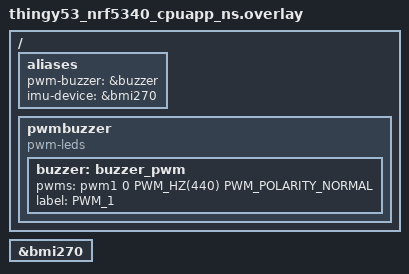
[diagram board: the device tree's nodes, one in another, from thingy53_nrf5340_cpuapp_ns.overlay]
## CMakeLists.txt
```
# SPDX-License-Identifier: Apache-2.0

cmake_minimum_required(VERSION 3.20.0)

find_package(Zephyr REQUIRED HINTS $ENV{ZEPHYR_BASE})
project(Gesture_Game)

target_sources(app PRIVATE src/main.c)
target_sources(app PRIVATE src/led.c)
target_sources(app PRIVATE src/button.c)
target_sources(app PRIVATE src/state_machine.c)
target_sources(app PRIVATE src/buzzer.c)
target_sources(app PRIVATE src/imu.c)
```

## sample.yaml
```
sample: 
  description: Gesture game for MES project
  name: Thingy53-NRF5340-network-MCU
type: mcu
arch: arm
supported:
  - watchdog
  - pwm
  - gpio
```

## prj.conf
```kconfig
# enable PWM
CONFIG_PWM=y

CONFIG_GPIO=y

CONFIG_SENSOR=y

#CONFIG_I2C=y
CONFIG_SPI=y
CONFIG_MULTITHREADING=y
CONFIG_NEWLIB_LIBC=y

CONFIG_NCS_SAMPLE_MCUMGR_BT_OTA_DFU=y
CONFIG_NCS_SAMPLE_MCUMGR_BT_OTA_DFU_SPEEDUP=y

#CONFIG_BT=y
#CONFIG_BT_PERIPHERAL=y
CONFIG_BT_DEVICE_NAME="Thingy53"
```

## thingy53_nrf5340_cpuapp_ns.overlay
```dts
// To get started, press Ctrl+Space to bring up the completion menu and view the available nodes.

// You can also use the buttons in the sidebar to perform actions on nodes.
// Actions currently available include:

// * Enabling / disabling the node
// * Adding the bus to a bus
// * Removing the node
// * Connecting ADC channels

// For more help, browse the DeviceTree documentation at https://docs.zephyrproject.org/latest/guides/dts/index.html
// You can also visit the nRF DeviceTree extension documentation at https://nrfconnect.github.io/vscode-nrf-connect/devicetree/nrfdevicetree.html

/ {
	aliases {
		pwm-buzzer = &buzzer;
		imu-device = &bmi270;
	};
	pwmbuzzer {
		compatible = "pwm-leds";
		status = "okay";
		buzzer:buzzer_pwm {
			pwms = <&pwm1 0 PWM_HZ(440) PWM_POLARITY_NORMAL>;
			label = "PWM_1";
		};
	};
};
&bmi270 {
	status = "okay";
};
```

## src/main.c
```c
/*
 * Copyright (c) 2012-2014 Wind River Systems, Inc.
 *
 * SPDX-License-Identifier: Apache-2.0
 */

#include <zephyr/kernel.h>
#include <zephyr/device.h>
#include <zephyr/drivers/pwm.h>
#include <zephyr/drivers/gpio.h>
#include <zephyr/drivers/sensor.h>
#include "buzzer.h"
#include "state_machine.h"
#include "imu.h"
#include "led.h"


int main(void)
{

	return 0;
}

// led is up: -9 And led is down: +9 looking for 9 -- gravity 9 m/s^2
// when there is no movement G should be close to 0. when there is movement and accel is settling 
// G should not be 0. The sum of squares of A is consistent if i'm not moving. This is the magnatitude
//
```

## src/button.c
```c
/*
 * Copyright (c) 2024
 *
 * SPDX-License-Identifier: Apache-2.0
 */


#include <zephyr/kernel.h>
#include <zephyr/drivers/gpio.h>
#include <zephyr/device.h>
#include "button.h"
#include "state_machine.h"

#define QUICK_PRESS_DEBOUNCE_TIME_MS   10

uint8_t num_presses = 0;
volatile uint8_t accept_button_presses = 0;

static const struct gpio_dt_spec sUser_btn = GPIO_DT_SPEC_GET(DT_ALIAS(sw0),gpios);
static struct gpio_callback button_cb_data;
static struct k_work timer_work;
static struct k_timer debounce_timer;

void button_debounce_workq_submit() // when timer expires submit for work to be done
{
    if (k_timer_remaining_get(&debounce_timer) == 0){
        k_work_submit(&timer_work);
    }
}
void button_workq()
{
    if (num_presses < 3){
        num_presses++;
    }
    else num_presses = 0;
}
static void button_press_isr(const struct device *dev, struct gpio_callback *cb, uint32_t pins)
{
    k_timer_start(&debounce_timer, K_MSEC(QUICK_PRESS_DEBOUNCE_TIME_MS), K_MSEC(0));
}

static void configure_button_interrupt()
{
    gpio_init_callback(&button_cb_data,button_press_isr,BIT(sUser_btn.pin));
	gpio_add_callback(sUser_btn.port, &button_cb_data);
}

static void configure_button_timer()
{
     /* Initialize button debounce timer work queue */
    k_work_init(&timer_work,button_workq);

    /* Initialize button debounce timer */
    k_timer_init(&debounce_timer,button_debounce_workq_submit, NULL);
}

static void button_gpio_init()
{
    int err; 
    if (!device_is_ready(sUser_btn.port)){
        printk("Error %d: failed to configure %s pin %d\n",
        err, sUser_btn.port->name,sUser_btn.pin);
    }

    err = gpio_pin_configure_dt(&sUser_btn,GPIO_INPUT);
	if (err != 0){
		printk("Error %d: failed to configure %s pin %d\n",
		err, sUser_btn.port->name, sUser_btn.pin);
	}

    err = gpio_pin_interrupt_configure_dt(&sUser_btn, GPIO_INT_EDGE_TO_ACTIVE);
	if (err !=0){
		printk("Error %d: failed to configure interrupt %s pin %d\n",
		err, sUser_btn.port->name, sUser_btn.pin);
	}
}

static int button_init()
{
    button_gpio_init();
    configure_button_timer();
    configure_button_interrupt();
    return 0;
}

SYS_INIT(button_init, APPLICATION, CONFIG_APPLICATION_INIT_PRIORITY);
```

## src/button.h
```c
/*
 * Copyright (c) 2024
 *
 * SPDX-License-Identifier: Apache-2.0
 */

#ifndef _BUTTON_H_
#define _BUTTON_H_

#include <zephyr/kernel.h>

void button_debounce_workq_submit();
void button_workq();

extern uint8_t num_presses;


#endif
```

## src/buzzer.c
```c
/*
 * Copyright (c) 2012-2014 Wind River Systems, Inc.
 *
 * SPDX-License-Identifier: Apache-2.0
 */

#include <zephyr/kernel.h>
#include <zephyr/init.h>
#include <zephyr/device.h>
#include <zephyr/drivers/pwm.h>
#include <zephyr/drivers/sensor.h>
#include <stdlib.h>
#include <time.h>
#include "buzzer.h"
#include "imu.h"
#include "utils.h"
#include "led.h"
#include "state_machine.h"

#define BUZZER_STACK                1024
#define STARTUP_NOTES               15
#define GOODBYE_NOTES               15
#define CONGRATES_NOTES             13
#define SEVEN_NOTES                 7
#define SIX_NOTES                   6
#define LOWER_BOUND                 0
#define UPPER_BOUND                 5
#define LEVEL_ONE_NOTES             10
#define LEVEL_TWO_NOTES             16
#define LEVEL_THREE_NOTES           22
#define HIGH_SCORE_LEVEL_ONE        5
#define HIGH_SCORE_LEVEL_TWO        8  
#define HIGH_SCORE_LEVEL_THREE      11

static const struct pwm_dt_spec sBuzzer = PWM_DT_SPEC_GET(DT_ALIAS(pwm_buzzer));
const char *ORIENTATION_STRING[SEVEN_NOTES] = {
    "UP", "DOWN", "RIGHT", "LEFT","RIGHTSIDE_UP", "UPSIDE_DOWN", "INVALID",
};

enum song_choice
{
    silence,
    startup_sound,
    congrats_sound,
    goodbye_sound,
    test
};
struct notes_highscore
{
    int notes_per_level;
    int highest_score;
};

struct note_duration
{   
    int note; // hz
    int duration; //
};

struct note_side
{   
    int note;
    int side;
    int duration; 
};

struct notes_highscore level1_scoreboard = {
    .notes_per_level= LEVEL_ONE_NOTES, .highest_score = HIGH_SCORE_LEVEL_ONE
};
struct notes_highscore level2_scoreboard = {
    .notes_per_level= LEVEL_TWO_NOTES,.highest_score = HIGH_SCORE_LEVEL_TWO
};
struct notes_highscore level3_scoreboard = {
    .notes_per_level= LEVEL_THREE_NOTES,.highest_score = HIGH_SCORE_LEVEL_THREE
};

struct note_side user_action[SIX_NOTES] = {
    {.note = A4, .side = up, .duration = whole },
    {.note = B4, .side = down, .duration = whole},
    {.note = C5, .side = right, .duration = whole},
    {.note = D5, .side = left, .duration = whole},
    {.note = E5, .side = rightside_up, .duration = whole},
    {.note = F5, .side = upside_down, .duration = whole}
};

struct note_duration startup_song[STARTUP_NOTES] = {
    {.note= F4, .duration = quarter},
    {.note= F4, .duration = quarter},
    {.note= G4, .duration = quarter},
    {.note= A4, .duration = quarter},
    {.note= Bb4, .duration = quarter},
    {.note= G4, .duration = quarter},
    {.note= F4, .duration = quarter},
    {.note= Bb4, .duration = quarter},
    {.note= Bb4, .duration = quarter},
    {.note= C5, .duration = quarter},
    {.note= D5, .duration = quarter},
    {.note= Bb4, .duration = quarter},
    {.note= C5, .duration = quarter},
    {.note= A4, .duration = quarter},
    {.note= Bb4, .duration = half_note}
};

struct note_duration goodbye_song[GOODBYE_NOTES] = {
    {.note= F4, .duration = eigth},
    {.note= F4, .duration = eigth},
    {.note= G4, .duration = eigth},
    {.note= A4, .duration = eigth},
    {.note= Bb4, .duration = eigth},
    {.note= G4, .duration = eigth},
    {.note= F4, .duration = eigth},
    {.note= Bb4, .duration = eigth},
    {.note= Bb4, .duration = eigth},
    {.note= C5, .duration = eigth},
    {.note= D5, .duration = eigth},
    {.note= Bb4, .duration = eigth},
    {.note= C5, .duration = eigth},
    {.note= A4, .duration = eigth},
    {.note= Bb4, .duration = quarter}
};

struct note_duration congrats_song[CONGRATES_NOTES] = {
    {.note= G4, .duration = quarter},
    {.note= G4, .duration = quarter},
    {.note= A4, .duration = eigth},
    {.note= Bb4, .duration = half_note},
    {.note= F4, .duration = quarter},
    {.note= F4, .duration = quarter},
    {.note= F4, .duration = quarter},
    {.note= C5, .duration = quarter},
    {.note= C5, .duration = quarter},
    {.note= C5, .duration = quarter},
    {.note= Bb4, .duration = eigth},
    {.note= A4, .duration = quarter},
    {.note= G4, .duration = whole}
};

enum song_choice eSong = silence; 
uint8_t tone_done = 0; 
volatile uint8_t user_won =0;

K_SEM_DEFINE(buzzer_initialize_sem, 0,1); // wait until buzzer is initiailzed 
K_SEM_DEFINE(play_game_sem, 0,1); // wait until the thread is called
K_MUTEX_DEFINE(tone_done_mutex); // wait until buzzer is initiailzed 

void buzzer_thread_func(void *d0,void *d1,void *d2)
{
    /* Block until buzzer is available */
    k_sem_take(&buzzer_initialize_sem,K_FOREVER); 
    while(1) 
    {
        switch (eSong)
        {
            case silence: 
                pwm_set_pulse_dt(&sBuzzer, 0);
                k_sleep(K_FOREVER);
                break;
            case startup_sound:
                printk("starting sound\r\n");
                k_mutex_lock(&tone_done_mutex, K_FOREVER);
                for (int i = 0; i < STARTUP_NOTES;i++)
                {
                    pwm_set_dt(&sBuzzer,PWM_HZ(startup_song[i].note),PWM_HZ(startup_song[i].note)/2U); 
                    k_msleep(startup_song[i].duration); // not sleeping the processor it's sleeping the thread. it's started the PWM. 
                }
                pwm_set_pulse_dt(&sBuzzer, 0);
                printk("in buzzer.done with start up tone\r\n");
                k_mutex_unlock(&tone_done_mutex);
                wake_state_machine_thd();
                k_sleep(K_FOREVER); // sleep the buzzer thread
                break;
            case goodbye_sound: 
                k_mutex_lock(&tone_done_mutex, K_FOREVER);
                for (int i = 0; i < GOODBYE_NOTES;i++)
                {
                    pwm_set_dt(&sBuzzer,PWM_HZ(goodbye_song[i].note),PWM_HZ(goodbye_song[i].note)/2U); 
                    k_msleep(goodbye_song[i].duration);
                }
                pwm_set_pulse_dt(&sBuzzer, 0);
                printk("in buzzer.done with goodbye tone\r\n");
                k_mutex_unlock(&tone_done_mutex);
                wake_state_machine_thd();
                k_sleep(K_FOREVER);
                break;
            case test: 
                k_mutex_lock(&tone_done_mutex, K_FOREVER);
                /*printk("side: %s\n", ORIENTATION_STRING[device_side]);
                for (int i = 0; i < SIX_NOTES;i++)
                {
                    if (device_side == user_action[i].side)
                    {
                        pwm_set_dt(&sBuzzer,PWM_HZ(user_action[i].note),PWM_HZ(user_action[i].note)/2U); 
                        k_msleep(user_action[i].duration);
                    }
                    else pwm_set_pulse_dt(&sBuzzer, 0);
                }
                pwm_set_pulse_dt(&sBuzzer, 0);*/
                k_mutex_unlock(&tone_done_mutex);
                break;
            case congrats_sound:
                k_mutex_lock(&tone_done_mutex, K_FOREVER);
                for (int i = 0; i < CONGRATES_NOTES;i++)
                {
                    pwm_set_dt(&sBuzzer,PWM_HZ(congrats_song[i].note),PWM_HZ(congrats_song[i].note)/2U); 
                    k_msleep(congrats_song[i].duration); // not sleeping the processor it's sleeping the thread. it's started the PWM. 
                }
                pwm_set_pulse_dt(&sBuzzer, 0);
                printk("in buzzer.done with congrats_sound\r\n");
                k_mutex_unlock(&tone_done_mutex);
                wake_state_machine_thd();
                k_sleep(K_FOREVER);
                break;
        }
        
    }
}
void play_level(struct notes_highscore sNotes_Higherscore)
{   
    uint8_t user_score = 0;
    int i = 0;
    int device_side;
    srand(time(NULL)); // initialization of random num generator 
    int rand_num;
    while(i < sNotes_Higherscore.notes_per_level)
    {
        rand_num = (rand() % (UPPER_BOUND - LOWER_BOUND + 1)) + LOWER_BOUND;
        pwm_set_dt(&sBuzzer,PWM_HZ(user_action[rand_num].note),PWM_HZ(user_action[rand_num].note)/2U);
        k_msleep(user_action[rand_num].duration);
        pwm_set_pulse_dt(&sBuzzer, 0);
        
        printk("PLAYED TONE. rotate to side:%s \r\n", ORIENTATION_STRING[user_action[rand_num].side]);
        device_side = imu_data_processing();
        
        printk("rotated to side:%s \r\n", ORIENTATION_STRING[device_side]);
        if (device_side == user_action[rand_num].side)
        {
            printk("Matched!\r\n");
            user_score++;
        }
        else {
            printk("Did not match!\r\n");
            led_error();
            pwm_set_dt(&sBuzzer,PWM_HZ(C4),PWM_HZ(C4)/2U);
            k_msleep(whole);
            pwm_set_pulse_dt(&sBuzzer, 0);
        }
        if (user_score >= sNotes_Higherscore.highest_score)
        {
            printk("User won!\r\n");
            user_won = 1;
        }
        else 
        {
            printk("still playing!\r\n");
            i++;
        }
    }
    printk("played the game..waking up state machine\r\n");
}


K_THREAD_DEFINE(buzzer_thd,BUZZER_STACK,buzzer_thread_func,NULL,NULL,NULL,THREAD1_PRIORITY,0,5000);

void play_startup_song()
{
    eSong = startup_sound;
    printk("woke up buzzer thread\r\n");
    k_wakeup(buzzer_thd);
    k_sleep(K_FOREVER); // sleep SM
}
void play_goodbye_song()
{
    eSong = goodbye_sound;
    k_wakeup(buzzer_thd);
    k_sleep(K_FOREVER);
}
void play_congrats_song()
{
    eSong = congrats_sound;
    k_wakeup(buzzer_thd);
    k_sleep(K_FOREVER); // sleep the SM
}
void play_test()
{
    eSong = test;
    k_wakeup(buzzer_thd);
    //k_sleep(K_FOREVER);
}
void play_silence()
{
    eSong = silence;
    k_wakeup(buzzer_thd);
   // k_sleep(K_FOREVER);
}

void wake_buzzer_thd()
{
    k_wakeup(buzzer_thd);
}

void play_level_one()
{
    k_sem_give(&play_game_sem);
    play_level(level1_scoreboard); // SM is not asleep here
}
void play_level_two()
{
    k_sem_give(&play_game_sem);
    play_level(level2_scoreboard); // SM is not asleep here
}
void play_level_three()
{
    k_sem_give(&play_game_sem);
    play_level(level3_scoreboard); // SM is not asleep here
}
static int buzzer_init()
{
    int ret = 0;
    if (!device_is_ready(sBuzzer.dev))
	{                          
		printk("Device %s is not ready.\r\n",sBuzzer.dev->name);
        ret = 1;
	}

    k_sem_give(&buzzer_initialize_sem);
    return 0;
}

SYS_INIT(buzzer_init, APPLICATION, CONFIG_APPLICATION_INIT_PRIORITY);
```

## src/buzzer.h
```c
#ifndef _BUZZER_H_
#define _BUZZER_H_

#include "utils.h"

extern void play_startup_song();
extern void play_congrats_song();
extern void play_goodbye_song();
extern void play_goodbye_song();
extern void play_test();
extern void play_silence();
extern void play_level_one();
extern void play_level_two();
extern void play_level_three();
extern void wake_buzzer_thd();
extern void device_side_translation();
extern uint8_t tone_done;
extern volatile uint8_t user_won;

enum orientation 
{
    up,
    down,
    right,
    left,
    rightside_up,
    upside_down, 
    invalid_side,
    invalid_gyr
};
extern enum orientation eSide;

#define whole       600 //whole note
#define eigth       75 //eigth note
#define quarter     150
#define half_note   300

#define C4  262
#define F4  349
#define G4  392
#define A4  440
#define Bb4 466
#define B4  494
#define C5  523
#define D5  587  
#define E5  659
#define F5  698
#define G5  784
#define A5  880

#define REST 1

#endif
```

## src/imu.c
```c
/*
 * Copyright (c) 2024
 *
 * SPDX-License-Identifier: Apache-2.0
 */
#include <zephyr/device.h>
#include <zephyr/init.h>
#include <zephyr/drivers/pwm.h>
#include <zephyr/drivers/gpio.h>
#include <zephyr/drivers/sensor.h>
#include <zephyr/kernel.h>
#include "imu.h"
#include "buzzer.h"
#include "state_machine.h"

#define IMU_STACK    1024
#define GRAVITY         9
#define NEG_GRAVITY    -9

static const struct device *sIMU_device = DEVICE_DT_GET_ONE(bosch_bmi270);
static struct sensor_value acc[3], gyr[3];
static struct sensor_value full_scale,sampling_freq,oversampling;
static int device_side;

K_SEM_DEFINE(imu_initialize_sem,0,1); // wait until buzzer is initiailzed 
K_MUTEX_DEFINE(imu_processing_mutex); // wait until buzzer is initiailzed 

static int imu_init()
{
    int err;
    if (!device_is_ready(sIMU_device))
    {
		printk("Error %d: failed to configure %s\n",
		err, sIMU_device->name);
	}

    full_scale.val1 = 2;            /* G maximum it can read. it's range/scale */ 
    full_scale.val2 = 0;
    sampling_freq.val1 = 15;       /* Hz. Performance mode. Faster = more sampling/note. Don't want to move fast */
    sampling_freq.val2 = 0;
    oversampling.val1 = 1;          /* Normal mode. oversample and filter out the extra data */
    oversampling.val2 = 0;

    /* Setting scale in G, due to loss of precision if the SI unit m/s^2
        * is used
        */
    sensor_attr_set(sIMU_device,SENSOR_CHAN_ACCEL_XYZ,SENSOR_ATTR_FULL_SCALE,&full_scale);
    sensor_attr_set(sIMU_device,SENSOR_CHAN_ACCEL_XYZ,SENSOR_ATTR_OVERSAMPLING,&oversampling);
    sensor_attr_set(sIMU_device,SENSOR_CHAN_ACCEL_XYZ,SENSOR_ATTR_SAMPLING_FREQUENCY,&sampling_freq);

    full_scale.val1 = 300;          /* dps. probably too fast */
    full_scale.val2 = 0;
    sampling_freq.val1 = 50;       /* Hz. Performance mode */
    sampling_freq.val2 = 0;
    oversampling.val1 = 1;          /* Normal mode */
    oversampling.val2 = 0;

    sensor_attr_set(sIMU_device,SENSOR_CHAN_GYRO_XYZ,SENSOR_ATTR_FULL_SCALE,&full_scale);
    sensor_attr_set(sIMU_device,SENSOR_CHAN_GYRO_XYZ,SENSOR_ATTR_OVERSAMPLING,&oversampling);
    sensor_attr_set(sIMU_device,SENSOR_CHAN_GYRO_XYZ,SENSOR_ATTR_SAMPLING_FREQUENCY,&sampling_freq);

    k_sem_give(&imu_initialize_sem);
    return 0;
}

void approx_sensor_position(struct sensor_value *acc_pos, struct sensor_value *gyr_pos)
{
   /* Use gyroscope to make sure it's not moving. You can get a false reading if the 
    user shakes the device)*/
    if ((gyr_pos[0].val1 < 1) & (gyr_pos[1].val1< 1) & (gyr_pos[2].val1< 1))
    {
        if ((acc_pos[2].val1 <= NEG_GRAVITY) & (acc_pos[1].val1 < GRAVITY) & (acc_pos[0].val1 < GRAVITY))
        {
            //printk("-z value! up! \r\n"); // -z = up +z = down 
             device_side = up;
        }
        else if ((acc_pos[2].val1 >= GRAVITY) & (acc_pos[1].val1 < GRAVITY)  & (acc_pos[0].val1 < GRAVITY))
        {
           //printk("+z value! down!\r\n"); // -z = up +z = down 
             device_side = down;
        }
        else if ((acc_pos[1].val1 <= NEG_GRAVITY) & (acc_pos[2].val1 < GRAVITY)  & (acc_pos[0].val1 < GRAVITY))
        {
           //printk("-y value! right! \r\n");  // yvalue
             device_side = right;
        }
        else if ((acc_pos[1].val1 >= GRAVITY) & (acc_pos[2].val1 < GRAVITY)  &  (acc_pos[0].val1 < GRAVITY))
        {
           // printk("+y value! left!\r\n"); 
             device_side = left;
        } 
        else if ((acc_pos[0].val1 <= NEG_GRAVITY) & (acc_pos[2].val1 < GRAVITY)  & (acc_pos[1].val1 < GRAVITY))
        {
           // printk("-x value! upside_down! \r\n"); // x value
             device_side = upside_down;
        }
        else if ((acc_pos[0].val1 >= GRAVITY) & (acc_pos[2].val1 < GRAVITY)  & (acc_pos[1].val1 < GRAVITY))
        {
           // printk("+x value! rightside_up!\r\n"); 
             device_side = rightside_up;
        }
        else
        {
             device_side = invalid_side; // on an invalid side
        }
    }
    else
    {
         device_side = invalid_gyr; // move the device too fast

    }
}

void imu_thread_func(void *d0, void *d1, void *d2)
{
    /* Block until imu is available */
    k_sem_take(&imu_initialize_sem,K_FOREVER); 

    while(1)
    {
        /*protect critical section of code without interrupts*/
        k_mutex_lock(&imu_processing_mutex, K_FOREVER);
        while (device_side == invalid_gyr)
        { // keep getting data
            sensor_sample_fetch(sIMU_device);
            sensor_channel_get(sIMU_device, SENSOR_CHAN_GYRO_XYZ, gyr);
            sensor_channel_get(sIMU_device, SENSOR_CHAN_ACCEL_XYZ, acc);

           /* printk("AX: %d.%06d, AY: %d.%06d, AZ: %d.%06d, \n",
                        "GX: %d.%06d, GY: %d.%06d, GZ: %d.%06d,\n",
                        acc[0].val1, acc[0].val2,
                        acc[1].val1, acc[1].val2,
                        acc[2].val1, acc[2].val2);
                        gyr[0].val1, gyr[0].val2,
                        gyr[1].val1, gyr[1].val2,
                        gyr[2].val1, gyr[2].val2);
            */
            approx_sensor_position(acc,gyr);
        }
        k_mutex_unlock(&imu_processing_mutex);
        wake_state_machine_thd(); // call the thread before going to sleep 
        k_sleep(K_FOREVER); // frees up whatever thread is ready to run
    }
}

K_THREAD_DEFINE(imu_thd,IMU_STACK,imu_thread_func,NULL,NULL,NULL,THREAD2_PRIORITY,0,5000);

int imu_data_processing()
{
    k_wakeup(imu_thd); // after i run the imu thread device side is ready to be read
    k_sleep(K_FOREVER); // SM to sleep. I can't go back to SM until the device side is valid.
    
    return device_side;
}

SYS_INIT(imu_init, APPLICATION, CONFIG_APPLICATION_INIT_PRIORITY);
```

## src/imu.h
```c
#ifndef _IMU_H_
#define _IMU_H_


void imu_thread_func(void *d0, void *d1, void *d2);
extern void imu_data_processing();
extern int device_side;

#endif
```

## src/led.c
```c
/*
 * Copyright (c) 2024
 *
 * SPDX-License-Identifier: Apache-2.0
 */

#include <zephyr/init.h>
#include <zephyr/kernel.h>
#include <zephyr/drivers/gpio.h>
#include <zephyr/device.h>
#include "state_machine.h"
#include "led.h"
#include "utils.h"

#define LED_ON                  1
#define LED_OFF                 0
#define ALIVE_LED_PERIOD        500
#define LED_STACK               500 

static const struct gpio_dt_spec sLED_Grn = GPIO_DT_SPEC_GET(DT_ALIAS(led1),gpios);
static const struct gpio_dt_spec sLED_Red = GPIO_DT_SPEC_GET(DT_ALIAS(led2),gpios);
enum eLED_state LED_state;

K_SEM_DEFINE(led_initialize_sem,0,1); // wait until LED is initiailzed 

int led_init()
{
    int err;
    if (!device_is_ready(sLED_Grn.port)){
		printk("Error %d: failed to configure %s pin %d\n",
		err, sLED_Grn.port->name,sLED_Grn.pin);
	}
	err = gpio_pin_configure_dt(&sLED_Grn, GPIO_OUTPUT_INACTIVE);
	if (err != 0){
		printk("Error %d: failed to configure %s pin %d\n",
		err, sLED_Grn.port->name, sLED_Grn.pin);
	}
    if (!device_is_ready(sLED_Red.port)){
		printk("Error %d: failed to configure %s pin %d\n",
		err, sLED_Red.port->name,sLED_Red.pin);
	}
	err = gpio_pin_configure_dt(&sLED_Red, GPIO_OUTPUT_INACTIVE);
	if (err != 0){
		printk("Error %d: failed to configure %s pin %d\n",
		err, sLED_Red.port->name, sLED_Red.pin);
	}
    k_sem_give(&led_initialize_sem);
    return err;
}

void led_thread_func(void *d0,void *d1,void *d2){
 
    k_sem_take(&led_initialize_sem,K_FOREVER); 
    printk("Semaphore taken in LED \r\n");
    uint32_t cnt = 0;
    while (1)
    {
        switch (LED_state)
        {
            case eLED_off:
                gpio_pin_set_dt(&sLED_Grn,LED_OFF);
                gpio_pin_set_dt(&sLED_Red,LED_OFF);
                wake_state_machine_thd();
                k_sleep(K_FOREVER); // the LED thread will go to sleep
                break;
            case eLED_on:
                gpio_pin_set_dt(&sLED_Grn,LED_ON);
                wake_state_machine_thd();
                k_sleep(K_FOREVER); // the LED thread will go to sleep
                break;
            case eLED_blinky: 
                gpio_pin_set_dt(&sLED_Grn,cnt%2);
                k_msleep(ALIVE_LED_PERIOD/2);
                cnt++; 
                break; 
            case eLED_error:
                gpio_pin_set_dt(&sLED_Red,LED_ON);
                wake_state_machine_thd();
                k_sleep(K_FOREVER); // the LED thread will go to sleep
                break;
        }
    }
}

K_THREAD_DEFINE(g_alive_thd,LED_STACK,led_thread_func,NULL,NULL,NULL,THREAD3_PRIORITY,0,5000);

void led_off()
{
    LED_state = eLED_off;
    k_wakeup(g_alive_thd);
    k_sleep(K_FOREVER); // turn of SM thread
    // turn off the current thread so that the LED thread can run or make it go to sleep for some time
}
void led_start()
{   
    LED_state = eLED_on;
    k_wakeup(g_alive_thd);
    k_sleep(K_FOREVER);
    // turn off the current thread so that the LED thread can run or make it go to sleep for some time
}
void led_blinky()
{
    LED_state = eLED_blinky;
    k_wakeup(g_alive_thd); // not sleep SM because want to blink while waiting for user input
    k_sleep(K_FOREVER); // turn of SM thread
}
void led_error()
{
    LED_state = eLED_error;
    k_wakeup(g_alive_thd); 
    k_sleep(K_FOREVER); // turn off the current thread 
}
SYS_INIT(led_init, APPLICATION, CONFIG_APPLICATION_INIT_PRIORITY);
```

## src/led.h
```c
/*
 * Copyright (c) 2024
 *
 * SPDX-License-Identifier: Apache-2.0
 */

#ifndef _LED_H_
#define _LED_H_

enum eLED_state
{
    eLED_off,
    eLED_on,
    eLED_blinky,
    eLED_error
};
extern enum eLED_state LED_state;
extern void led_off();
extern void led_start();
extern void led_blinky();
extern void led_error();

#endif
```

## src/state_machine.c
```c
/*
 * Copyright (c) 2024
 *
 * SPDX-License-Identifier: Apache-2.0
 */


#include <zephyr/init.h>
#include <zephyr/kernel.h>
#include "state_machine.h"
#include "led.h"
#include "button.h"
#include "imu.h"
#include "buzzer.h"
#include "utils.h"

#define STATE_MACHINE_STACK     1024 
static struct k_work select_level_work;
static struct k_timer select_level_timer;
enum state currentState = START;

K_SEM_DEFINE(state_machine_sem, 0,1); // wait until buzzer is initiailzed 

int state_machine_init()
{
    /* work job for selecting level */
    k_work_init(&select_level_work,select_level_workq);
    /* Initialize timer for selecting a level */
    k_timer_init(&select_level_timer,select_level_workq_submit, NULL);
    k_sem_give(&state_machine_sem);
    return 0;
}

void state_machine_func(void *d0,void *d1,void *d2)
{
    /* Block until state_machine is initialized */
    k_sem_take(&state_machine_sem,K_FOREVER); 
    while (1)
    {
        switch (currentState)
        {
           // case TEST: 
                //imu_data_processing();
            //break;
            case START:
                led_start();
                play_startup_song();
                next_state(ePICKLEVEL);
            break;
            case ePICKLEVEL:
            /* The timer must start before the blinky otherwise it is impossible to have a blinky while trying to start the timer
            When the timer is done it will stop the blinky */
               k_timer_start(&select_level_timer, K_MSEC(7000), K_MSEC(0)); // 10s to pick a level
               led_blinky();
            break;
            case eLEVEL1: 
                led_off(); 
                play_level_one(); // this is part of the state machine thread because it's called from the SM. 
                // it dosen't matter what file it is called from it matters where it is called from 
                printk("Return from playing LEVEL 1!\r\n");
                if (user_won)
                {
                    play_congrats_song();
                    user_won = 0;
                    next_state(eLEVEL2);
                }
                else 
                {
                    next_state(END);
                }
             break;
            case eLEVEL2:
                printk("SM:Level 2!\r\n");
                play_level_two();
                printk("Return from playing LEVEL 2!\r\n");
                if (user_won)
                {
                    play_congrats_song();
                    user_won = 0;
                    next_state(eLEVEL3);
                }
                else 
                {
                    next_state(END);
                }
            break;
            case eLEVEL3:
                printk("SM:Level 3!\r\n");
                play_level_three();
                printk("Return from playing LEVEL 3!\r\n");
                if (user_won)
                {
                    play_congrats_song();
                    user_won = 0;
                    next_state(END);
                }
                else 
                {
                    next_state(END);
                }
            break;
            case END:
                play_goodbye_song();
                play_silence();
            break; 
        } 
    }
}

K_THREAD_DEFINE(state_machine_thd,STATE_MACHINE_STACK,state_machine_func,NULL,NULL,NULL,THREAD0_PRIORITY ,0,5000);

void next_state(enum state nextState)
{
    switch(nextState)
    {
        case START: 
            break;
        case ePICKLEVEL:
            printk("Next state:PICK_LEVEL!\r\n");
            currentState = ePICKLEVEL;
            k_wakeup(state_machine_thd); // to keep it from sleeping when it returns from this function and breaks.
            break;
        case eLEVEL1:
            printk("Next state:LEVEL 1!\r\n");
            currentState = eLEVEL1;
            k_wakeup(state_machine_thd);
            break;
        case eLEVEL2:
            currentState = eLEVEL2;
            k_wakeup(state_machine_thd);
            break;
        case eLEVEL3:
            currentState = eLEVEL3;
            k_wakeup(state_machine_thd);
            break;
        case END:
            printk("Next state:END!\r\n");
            currentState = END;
            k_wakeup(state_machine_thd);
            break;
    }
}

void select_level_workq_submit() // when timer expires submit for work to be done
{
    if (k_timer_remaining_get(&select_level_timer) == 0){
        k_work_submit(&select_level_work);
    }
}

void select_level_workq()
{
    if (num_presses == 0){
        k_timer_start(&select_level_timer, K_MSEC(8000), K_MSEC(0)); // restart the timer to keep waiting
    }
    if (num_presses == 1){  
        //printk("Selected level 1!\r\n"); 
        next_state(eLEVEL1);
    }
    if (num_presses == 2){
        //printk("Selected level 2!\r\n"); 
        next_state(eLEVEL1);
    }
    if (num_presses == 3){
        // printk("Selected level 3!\r\n"); 
        next_state(eLEVEL3);
    }
}

void wake_state_machine_thd()
{
    k_wakeup(state_machine_thd);
}

SYS_INIT(state_machine_init, APPLICATION, CONFIG_APPLICATION_INIT_PRIORITY);
```

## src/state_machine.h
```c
#ifndef _STATE_MACHINE_H_
#define _STATE_MACHINE_H_

enum state {
    START,
    ePICKLEVEL,
    eLEVEL1,
    eLEVEL2,
    eLEVEL3,
    END
};

void next_state(enum state nextState);
void select_level_workq_submit();
void select_level_workq();
void state_machine_func();
extern void wake_state_machine_thd();

#endif
```

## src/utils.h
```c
#define THREAD0_PRIORITY    7   // state machine 
#define THREAD1_PRIORITY    7   // buzzer
#define THREAD2_PRIORITY    7   // imu
#define THREAD3_PRIORITY    7   // led
#define THREAD4_PRIORITY    7     // led
```
